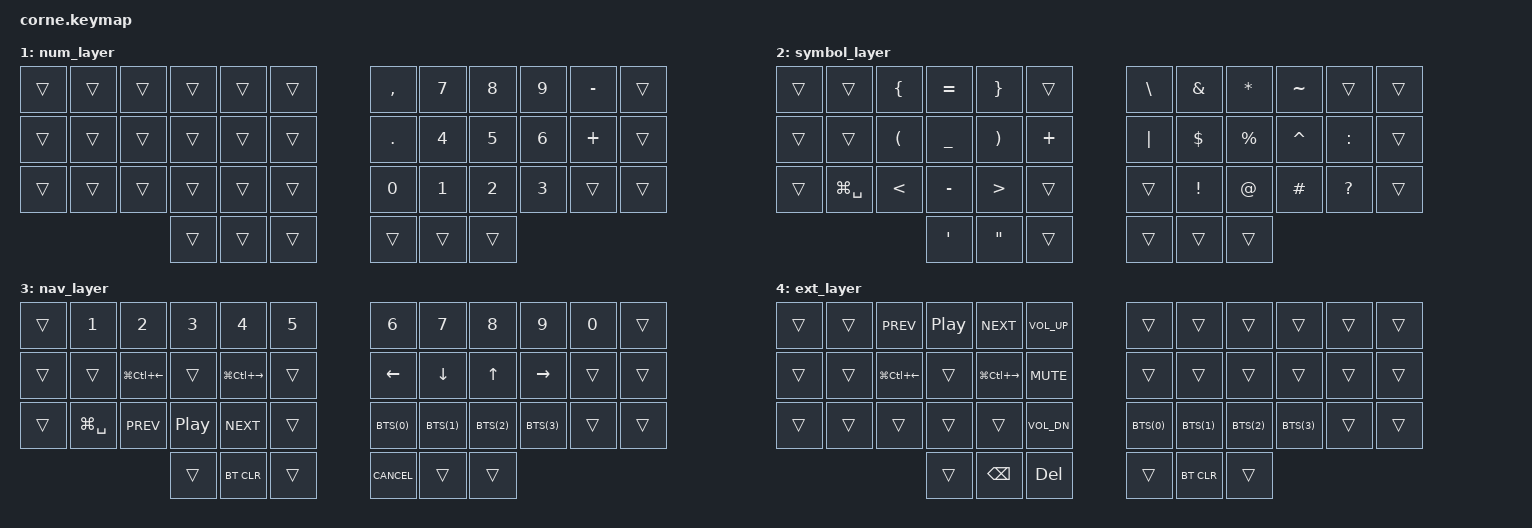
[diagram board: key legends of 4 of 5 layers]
/*
 * Copyright (c) 2020 The ZMK Contributors
 *
 * SPDX-License-Identifier: MIT
 */

#include <behaviors.dtsi>
#include <behaviors/num_word.dtsi>
#include <dt-bindings/zmk/keys.h>
#include <dt-bindings/zmk/bt.h>

#define DEF 0
#define NUM 1
#define SYM 2
#define NAV 3
#define EXT 4

// left hand keys with thumb cluster
#define LHK 0 1 2 3 4  5     12 13 14 15 16 17    24 25 26 27 28 29    36 37 38   39 40 41
// right hand keys with thum cluster
#define RHK 6 7 8 9 10 11    18 19 20 21 22 23    30 31 32 33 34 35    39 40 41   38 37 36

#define LHMR(K1,K2,K3,K4) &lh_hm LGUI K1    &lh_hm LALT K2   &lh_hm LCTRL K3   &lh_hm LSHFT K4
#define RHMR(K1,K2,K3,K4) &rh_hm LSHFT K1    &rh_hm LCTRL K2   &rh_hm LALT K3   &rh_hm LGUI K4



#define BTS(num) &bt BT_SEL num

#define TAPPING_TERM 220

/ {
    behaviors {
        bspc_del: backspace_delete {
            compatible = "zmk,behavior-mod-morph";
            #binding-cells = <0>;
            bindings = <&kp BACKSPACE>, <&kp DELETE>;
            mods = <(MOD_LSFT|MOD_RSFT)>;
            keep-mods = <(MOD_RSFT)>;
        };
        bmo: holdtap_balanced_mo {
            compatible = "zmk,behavior-hold-tap";
            #binding-cells = <2>;
            bindings = <&mo>, <&kp>;
            tapping-term-ms = <TAPPING_TERM>;
            quick-tap-ms = <200>;
            flavor = "balanced";
        };
        lh_hm: left_positional_home_row {
            compatible = "zmk,behavior-hold-tap";
            #binding-cells = <2>;
            flavor = "balanced";
            tapping-term-ms = <TAPPING_TERM>;
            quick-tap-ms = <200>;
            require-prior-idle-ms = <110>;
            bindings = <&kp>, <&kp>;
            hold-trigger-key-positions = <RHK>;    // <---[[right-hand keys]]
            hold-trigger-on-release;
        };
        rh_hm: right_positional_home_row {
            compatible = "zmk,behavior-hold-tap";
            #binding-cells = <2>;
            flavor = "balanced";
            tapping-term-ms = <TAPPING_TERM>;
            quick-tap-ms = <200>;
            require-prior-idle-ms = <110>;
            bindings = <&kp>, <&kp>;
            hold-trigger-key-positions = <LHK>;    // <---[[left-hand keys]]
            hold-trigger-on-release;
        };
        ltc: layer_tap_custom {
            compatible = "zmk,behavior-hold-tap";
            #binding-cells = <2>;
            flavor = "hold-preferred";
            tapping-term-ms = <TAPPING_TERM>;
            quick-tap-ms = <200>;
            bindings = <&mo>, <&kp>;
        };
        sht: space_hold_tap {
            compatible = "zmk,behavior-hold-tap";
            #binding-cells = <2>;
            flavor = "hold-preferred";
            tapping-term-ms = <TAPPING_TERM>;
            require-prior-idle-ms = <140>;
            quick-tap-ms = <200>;
            bindings = <&mo>, <&kp>;
        };
        // num-word
        num_dance: num_dance {
            compatible = "zmk,behavior-tap-dance";
            #binding-cells = <0>;
            tapping-term-ms = <230>;
            bindings = <&num_word NUM>, <&sl NUM>;
        };
        smart_num: smart_num { // num-word on tap, &mo on hold, sl on double tap
            compatible = "zmk,behavior-hold-tap";
            #binding-cells = <2>;
            flavor = "hold-preferred";
            tapping-term-ms = <TAPPING_TERM>;
            quick-tap-ms = <200>;
            bindings = <&mo>, <&num_dance>;
        };
        smart_shift: smart_shift {
            compatible = "zmk,behavior-mod-morph";
            #binding-cells = <0>;
            bindings = <&sk LSHFT>, <&caps_word>;
            mods = <(MOD_LSFT)>;
        };
    };
};

&num_word {  // num-word, requires PR #1451( used urob fork )
    continue-list = <BSPC DEL DOT COMMA PLUS MINUS STAR FSLH EQUAL>;
};
&sk {  // sticky-key config
    quick-release; // no double capitalization when rolling keys
};



#define NEXT_DESKTOP &kp LG(LC(RIGHT))
#define PREV_DESKTOP &kp LG(LC(LEFT))
#define SMART_NUM_SYM &smart_num SYM 0

#define COMBOS_TIMEOUT_SHORT 20
#define COMBOS_TIMEOUT_MEDIUM 25
#define COMBOS_TIMEOUT_LONG 60
#define MK_COMBO(NAME,KEYS,RESULT,TIMEOUT) NAME {\
    timeout-ms = <TIMEOUT>;\
    key-positions = <KEYS>;\
    bindings = <RESULT>;\
}


/ {
    combos {
        compatible = "zmk,combos";
        combo_BACKSPACE {
            timeout-ms = <30>;
            key-positions = <7 8>;
            bindings = <&kp BACKSPACE>;
        };
        combo_DEL {
            timeout-ms = <COMBOS_TIMEOUT_SHORT>;
            key-positions = <8 9>;
            bindings = <&kp DELETE>;
        };

        MK_COMBO(combo_1,1 13,&kp N1, COMBOS_TIMEOUT_LONG);
        MK_COMBO(combo_2,2 14,&kp N2, COMBOS_TIMEOUT_LONG);
        MK_COMBO(combo_3,3 15,&kp N3, COMBOS_TIMEOUT_LONG);
        MK_COMBO(combo_4,4 16,&kp N4, COMBOS_TIMEOUT_LONG);
        MK_COMBO(combo_5,5 17,&kp N5, COMBOS_TIMEOUT_LONG);
        MK_COMBO(combo_6,6 18,&kp N6, COMBOS_TIMEOUT_LONG);
        MK_COMBO(combo_7,7 19,&kp N7, COMBOS_TIMEOUT_LONG);
        MK_COMBO(combo_8,8 20,&kp N8, COMBOS_TIMEOUT_LONG);
        MK_COMBO(combo_9,9 21,&kp N9, COMBOS_TIMEOUT_LONG);
        MK_COMBO(combo_0,10 22,&kp N0, COMBOS_TIMEOUT_LONG);

        MK_COMBO(combo_GRAVE,1 2,&kp GRAVE, 35); // ё
        MK_COMBO(combo_SQT,20 21,&kp SQT, 30); // э
        MK_COMBO(combo_LBKT,27 28,&kp LBKT, 33); // х
        MK_COMBO(combo_RBKT,31 32,&kp RBKT, 33); // ъ
        MK_COMBO(combo_ESC,19 20,&kp ESC, 25);
        //MK_COMBO(combo_TAB,15 16,&kp TAB, 25);
        MK_COMBO(combo_ENTER,15 16,&kp ENTER, 25);
    };
};

/ {
        keymap {
                compatible = "zmk,keymap";

                default_layer {
                        bindings = <
// .---------------------------------------------------------------------------------------------------------------------------------------.
// |          |          |          |          |          |          | | |          |          |          |          |          |          |
         &none  &kp Q     &kp W      &kp E      &kp R      &kp T          &kp Y      &kp U      &kp I       &kp O      &kp P     &none
// |          |          |          |          |          |          | | |          |          |          |          |          |          |
        &none   LHMR(A,       S,        D,          F)      &kp G          &kp H      RHMR(J,       K,         L,         SEMI)   &none
// |          |          |          |          |          |          | | |          |          |          |          |          |          |
    &none       &kp Z      &kp X      &kp C      &kp V      &kp B          &kp N      &kp M      &kp COMMA   &kp DOT   &kp FSLH    &none
// |          |          |          |          |          |          | | |          |          |          |          |          |          |
// '---------------------------------------------------------------------------------------------------------------------------------------'
//                         |             |             |             | | |             |             |             |
                              &kp LBKT  &mt LSHFT TAB  &sht NAV SPACE     SMART_NUM_SYM  &smart_shift    &kp RBKT
//                         |             |             |             | | |             |             |             |
//                         '---------------------------------------------------------------------------------------'
                        >;
                };
                num_layer {
                        bindings = <
// .---------------------------------------------------------------------------------------------------------------------------------------.
// |          |          |          |          |          |          | | |          |          |          |          |          |          |
      &trans     &trans     &trans      &trans   &trans      &trans         &kp COMMA   &kp N7   &kp N8     &kp N9    &kp MINUS    &trans
// |          |          |          |          |          |          | | |          |          |          |          |          |          |
      &trans   &trans     &trans       &trans    &trans      &trans         &kp DOT   &kp N4    &kp N5     &kp N6      &kp PLUS    &trans
// |          |          |          |          |          |          | | |          |          |          |          |          |          |
      &trans   &trans     &trans        &trans   &trans      &trans         &kp N0      &kp N1      &kp N2    &kp N3    &trans   &trans
// |          |          |          |          |          |          | | |          |          |          |          |          |          |
// '---------------------------------------------------------------------------------------------------------------------------------------'
//                         |             |             |             | | |             |             |             |
                               &trans      &trans         &trans           &trans         &trans        &trans
//                         |             |             |             | | |             |             |             |
//                         '---------------------------------------------------------------------------------------'
                        >;
                };

                symbol_layer {
                        bindings = <
// .---------------------------------------------------------------------------------------------------------------------------------------.
// |          |          |          |          |          |          | | |          |          |          |          |          |          |
    &trans      &trans     &kp LBRC  &kp EQUAL   &kp RBRC    &trans         &kp BSLH     &kp AMPS  &kp STAR  &kp TILDE     &trans    &trans
// |          |          |          |          |          |          | | |          |          |          |          |          |          |
      &trans   &trans     &kp LPAR   &kp UNDER   &kp RPAR   &kp PLUS       &kp PIPE  &kp DOLLAR  &kp PRCNT  &kp CARET  &kp COLON  &trans
// |          |          |          |          |          |          | | |          |          |          |          |          |          |
       &trans &kp LG(SPACE)  &kp LT    &kp MINUS     &kp GT    &trans         &trans    &kp EXCL   &kp AT     &kp HASH  &kp QMARK    &trans
// |          |          |          |          |          |          | | |          |          |          |          |          |          |
// '---------------------------------------------------------------------------------------------------------------------------------------'
//                         |             |             |             | | |             |             |             |
                               &kp SQT      &kp DQT       &trans           &trans      &trans         &trans
//                         |             |             |             | | |             |             |             |
//                         '---------------------------------------------------------------------------------------'
                        >;
                };

                nav_layer {
                        bindings = <
// .---------------------------------------------------------------------------------------------------------------------------------------.
// |          |          |          |          |          |          | | |          |          |          |          |          |          |
     &trans      &kp N1    &kp N2      &kp N3     &kp N4     &kp N5        &kp N6      &kp N7     &kp N8     &kp N9     &kp N0      &trans
// |          |          |          |          |          |          | | |          |          |          |          |          |          |
     &trans    &trans    PREV_DESKTOP  &trans  NEXT_DESKTOP &trans         &kp LEFT   &kp DOWN   &kp UP     &kp RIGHT  &trans      &trans
// |          |          |          |          |          |          | | |          |          |          |          |          |          |
      &trans  &kp LG(SPACE)    &kp C_PREV  &kp C_PP   &kp C_NEXT   &trans        BTS(0)      BTS(1)     BTS(2)    BTS(3)    &trans    &trans
// |          |          |          |          |          |          | | |          |          |          |          |          |          |
// '---------------------------------------------------------------------------------------------------------------------------------------'
//                         |             |             |             | | |             |             |             |
                              &trans      &bt BT_CLR         &trans       &kp K_CANCEL       &trans      &trans
//                         |             |             |             | | |             |             |             |
//                         '---------------------------------------------------------------------------------------'
                        >;
                };

                ext_layer {
                        bindings = <
// .---------------------------------------------------------------------------------------------------------------------------------------.
// |          |          |          |          |          |          | | |          |          |          |          |          |          |
     &trans     &trans  &kp C_PREV  &kp C_PP   &kp C_NEXT  &kp C_VOL_UP    &trans    &trans     &trans     &trans      &trans      &trans
// |          |          |          |          |          |          | | |          |          |          |          |          |          |
     &trans    &trans    PREV_DESKTOP  &trans  NEXT_DESKTOP &kp C_MUTE  &trans     &trans   &trans     &trans      &trans      &trans
// |          |          |          |          |          |          | | |          |          |          |          |          |          |
      &trans     &trans    &trans     &trans     &trans   &kp C_VOL_DN      BTS(0)      BTS(1)     BTS(2)    BTS(3)     &trans    &trans
// |          |          |          |          |          |          | | |          |          |          |          |          |          |
// '---------------------------------------------------------------------------------------------------------------------------------------'
//                         |             |             |             | | |             |             |             |
                               &trans     &kp BACKSPACE    &kp DELETE        &trans         &bt BT_CLR    &trans
//                         |             |             |             | | |             |             |             |
//                         '---------------------------------------------------------------------------------------'
                        >;
                };
        };
};
